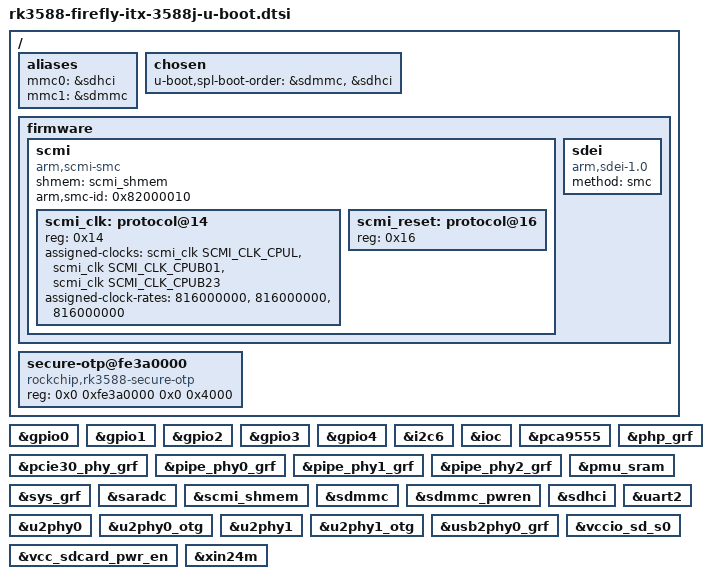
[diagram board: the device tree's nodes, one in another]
// SPDX-License-Identifier: (GPL-2.0+ OR MIT)
/*
 * Copyright (c) 2023 Collabora Ltd.
 */

#include "rk3588-u-boot.dtsi"
#include "rk3588-firefly-itx-3588j-i2c6.dtsi"

/ {
	aliases {
		mmc0 = &sdhci;
		mmc1 = &sdmmc;
	};

	chosen {
		u-boot,spl-boot-order = &sdmmc, &sdhci;
	};

	firmware: firmware {
		scmi: scmi {
			compatible = "arm,scmi-smc";
			shmem = <&scmi_shmem>;
			arm,smc-id = <0x82000010>;
			#address-cells = <1>;
			#size-cells = <0>;

			scmi_clk: protocol@14 {
				reg = <0x14>;
				#clock-cells = <1>;

				assigned-clocks = <&scmi_clk SCMI_CLK_CPUL>, <&scmi_clk SCMI_CLK_CPUB01>,
				                  <&scmi_clk SCMI_CLK_CPUB23>;
				assigned-clock-rates = <816000000>, <816000000>, <816000000>;
			};

			scmi_reset: protocol@16 {
				reg = <0x16>;
				#reset-cells = <1>;
			};
		};

		sdei: sdei {
			compatible = "arm,sdei-1.0";
			method = "smc";
		};
	};

	secure-otp@fe3a0000 {
		bootph-pre-ram;
		compatible = "rockchip,rk3588-secure-otp";
		reg = <0x0 0xfe3a0000 0x0 0x4000>;
	};

};

&firmware {
	bootph-pre-ram;
	status = "okay";
};

&gpio0 {
	bootph-pre-ram;
	status = "okay";
};

&gpio1 {
	bootph-all;
	status = "okay";
};

&gpio2 {
	bootph-all;
	status = "okay";
};

&gpio3 {
	bootph-all;
	status = "okay";
};

&gpio4 {
	bootph-all;
	status = "okay";
};

&i2c6 {
	bootph-pre-ram;
};

&ioc {
	bootph-pre-ram;
};

&pca9555 {
	bootph-pre-ram;
};

// This was used in the BSP 2017 U-Boot. It offers accelerated
// crypto performed in hardware, but the driver model DM_CRYPTO does
// not exist anymore. Disabling it until someone(tm) can perform
// the adaption to the new DM_HASH etc. models.
/*&crypto {
    bootph-pre-ram;
    status = "okay";
}; */

&pcie30_phy_grf {
	bootph-all;
	status = "okay";
};

&php_grf {
	bootph-all;
	status = "okay";
};

&pipe_phy0_grf {
	bootph-all;
	status = "okay";
};

&pipe_phy1_grf {
	bootph-all;
	status = "okay";
};

&pipe_phy2_grf {
	bootph-all;
	status = "okay";
};

&pmu_sram {
	bootph-pre-ram;
};

&sys_grf {
	bootph-pre-ram;
	status = "okay";
};

// This was used in the BSP 2017 U-Boot. It offers accelerated
// decompression, but was implemented as a non-standard DM_MISC driver
// plus some possible non-upstreamable patches to the U-Boot core.
// Disabling it until someone(tm) can adapt it.
/*&hw_decompress {
    bootph-pre-ram;
    status = "okay";
};*/

//&rng {
//    bootph-all;
//    status = "okay";
//};

&saradc {
	bootph-all;
};

&scmi {
	bootph-pre-ram;
};

&scmi_clk {
	bootph-pre-ram;
};

&scmi_shmem {
	bootph-pre-ram;
};

&sdmmc {
	bootph-pre-ram;
};

&sdmmc_pwren {
	bootph-pre-ram;
};

&sdhci {
	bootph-pre-ram;
	status = "okay";
};

// DEBUG-Port
&uart2 {
	bootph-pre-ram;
	status = "okay";
};

&u2phy0 {
	bootph-all;
	status = "okay";
};

&u2phy0_otg {
	bootph-all;
};

&u2phy1 {
	status = "okay";
};

&u2phy1_otg {
	status = "okay";
};

&usb2phy0_grf {
	bootph-all;
};

&vcc_sdcard_pwr_en {
	bootph-pre-ram;
};

&vccio_sd_s0 {
	bootph-pre-ram;
};

&xin24m {
	bootph-all;
	status = "okay";
};
